# Polarfire SoC register map
Vendor: Microchip; File version: 1.0
CPU: Microchip PolarFire SoC 1.0, little endian
Registers are 32-bit, read-write, reset 0x0 unless marked. A register's access mark holds for its fields unless they carry their own. Offsets are from the block's base; [hi:lo] are bit positions; {n}, {i} and the like mark numbered series; 'fields as' and 'values as' point back to an identical list.

## SYSREG — SYSREG Controller
Base 0x20002000
0x00 TEMP0 reset 0xAC7E1 — Register for software use
  [31:0] DATA — Scratch register for CPUS
0x04 TEMP1 — Register for software use
  [31:0] DATA — Scratch register for CPUS
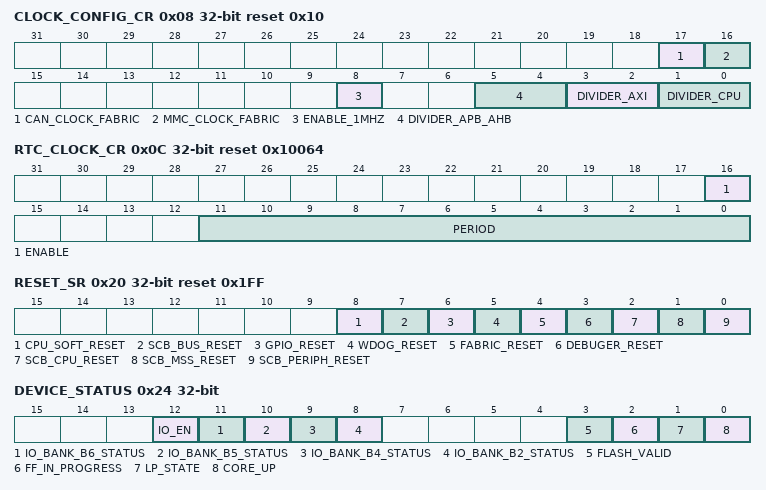
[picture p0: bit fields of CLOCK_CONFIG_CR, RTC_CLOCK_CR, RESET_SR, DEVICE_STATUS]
0x08 CLOCK_CONFIG_CR reset 0x10 — Master clock configuration
  [17] CAN_CLOCK_FABRIC
  [16] MMC_CLOCK_FABRIC
  [8] ENABLE_1MHZ — When '1' requests pfsoc_control to enable the 1mHz (2MHz) on-chip oscillator
  [5:4] DIVIDER_APB_AHB — Sets the master synchronous clock divider AHB/APB clock divider (Reset=/2 =1) 00=/1 01=/2 10=/4 11=/8 (AHB/APB divider may not be set to /1)
  [3:2] DIVIDER_AXI — Sets the master synchronous clock divider for AXI clock divider (Reset=/1 =0)
  [1:0] DIVIDER_CPU — Sets the master synchronous clock divider for CPU (Reset=/1 =0). Note at reset MSS corner clock is 80MHz, therefore divider is set to divide by 1
0x0C RTC_CLOCK_CR reset 0x10064 — RTC clock divider
  [16] ENABLE — RTC Clock enable. When chaning the divider the enable should be trurned off first, the divider changed and the enable turned back on.
  [11:0] PERIOD — Sets the division ratio to create the internal RTC clock from the reference clock. The defaults sets the reference clock to 1MHz assuming the reference clock is 100Mhz. If the reference clock is 125MHz then 125 will create a 1MHz clock Max divider value is 4095 and value must be an integer. RTC clock must be less 2X the AXI clock rate.
0x10 FABRIC_RESET_CR — Fabric Reset mask
  [0] ENABLE — This bitfield has no affect if changed
0x14 BOOT_FAIL_CR
  [0] BOOT — Written by firmware to indicate that the boot process failed, drives the fab_boot_fail signal to the fabric. Is cleared by the fabric asserting fab_boot_fail_clear
0x18 MSS_RESET_CR — Allows the CPU to fully reset the MSS
  [15:0] RESET_VALUE — When written to 16'hDEAD will cause a full MSS reset. The Reset wil clear this register. The register may be writtent to any value but only a value off 16'hDEAD will cause the reset to happen
0x1C CONFIG_LOCK_CR — Configuration lock
  [0] LOCK — When written to '1' will cause all RWC registers to lock until a master reset occurs.
0x20 RESET_SR reset 0x1FF — Indicates which reset caused the last reset. After a reset occurs register should be read and then zero written to allow the next reset event to be correctly captured.
  [8] CPU_SOFT_RESET — Indicates that the CPU reset ths MSS using the soft reset register
  [7] SCB_BUS_RESET — Indicates that SCB bus reset occurred (which causes warm reset of MSS)
  [6] GPIO_RESET — Indicates that fabric asserted the GPIO reset inputs
  [5] WDOG_RESET — Reset was caused by the watchdog
  [4] FABRIC_RESET — Reset was caused by the fabric
  [3] DEBUGER_RESET — Reset was caused by the Risc-V Debugger
  [2] SCB_CPU_RESET — Reset was caused by the SCB CPU reset register
  [1] SCB_MSS_RESET — Reset was caused by the SCB MSS reset register
  [0] SCB_PERIPH_RESET — Reset was caused by the SCB periphery reset signal
0x24 DEVICE_STATUS ro — Indicates the device status, in particular the state of the FPGA fabric and the MSS IO banks
  [12] IO_EN — Indicates the status of the io_en input from G5 Control.
  [11] IO_BANK_B6_STATUS — Power status of IO bank 6
  [10] IO_BANK_B5_STATUS — Power status of IO bank 5
  [9] IO_BANK_B4_STATUS — Power status of IO bank 4
  [8] IO_BANK_B2_STATUS — Power status of IO bank 2
  [3] FLASH_VALID — Indicates the status of the flash_valid input from G5 Control.
  [2] FF_IN_PROGRESS — Indicates the status of the ff_in_progress input from G5 Control.
  [1] LP_STATE — Indicates the status of the lp_state input from G5 Control.
  [0] CORE_UP — Indicates the status of the core_up input from G5 Control.
0x28 MSS_BUILD ro — MSS Build Info
  [31:0] REVISION — Set to the SVN revision of the pfsoc_mss_main.sv file
{0x3C+4i} FAB_INTEN_U54_{i} (i=1..4) — U54-{i} Fabric interrupt enable
  [31:0] ENABLE — Enables the F2H_interrupts[31:0] to interrupt U54_1 directly
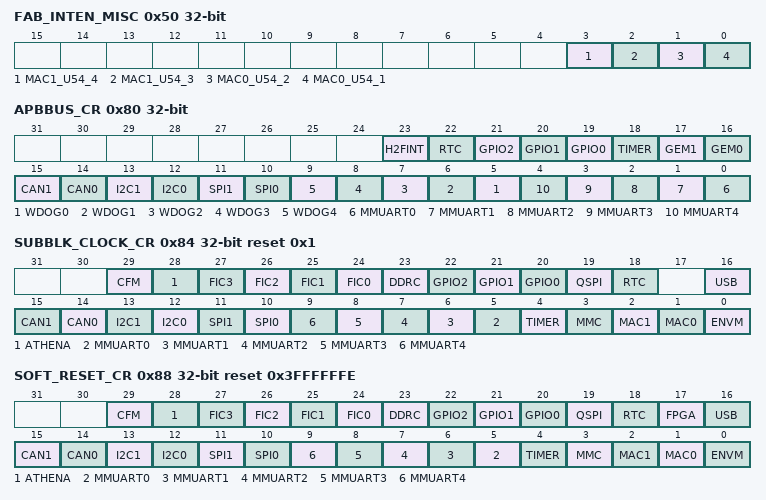
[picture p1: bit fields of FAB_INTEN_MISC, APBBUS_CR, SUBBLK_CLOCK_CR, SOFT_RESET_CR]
0x50 FAB_INTEN_MISC — Allows the Ethernat interrupts to be directly routed to the U54 CPUS.
  [3] MAC1_U54_4 — Enables the Ethernet MAC1 to interrupt U54_1 directly
  [2] MAC1_U54_3 — Enables the Ethernet MAC1 to interrupt U54_1 directly
  [1] MAC0_U54_2 — Enables the Ethernet MAC0 to interrupt U54_1 directly
  [0] MAC0_U54_1 — Enables the Ethernet MAC0 to interrupt U54_1 directly
0x54 GPIO_INTERRUPT_FAB_CR — Switches GPIO interrupt from PAD to Fabric GPIO
  [31:0] SELECT — Setting these bits will disable the Pad interrupt, and enable the fabric GPIO interrupt for bits 31:0. When the bit is set the Pad interrupt will be ORED into the GPIO0 & GPIO1 non-direct interrupts. When the bit is not set the Fabric interrupt is ORED into the GPIO2 non-direct interrupt. To prevent ORING then the interrupt should not be enabled in the GPIO block
0x80 APBBUS_CR — AMP Mode peripheral mapping register. When the register bit is '0' the peripheral is mapped into the 0x2000000 address range using AXI bus 5 from the Coreplex. When the register bit is '1' the peripheral is mapped into the 0x28000000 address range using AXI bus 6 from the Coreplex.
  [23] H2FINT, [22] RTC, [21] GPIO2, [20] GPIO1, [19] GPIO0, [18] TIMER, [17] GEM1, [16] GEM0, [15] CAN1, [14] CAN0, [13] I2C1, [12] I2C0, [11] SPI1, [10] SPI0, [n+5] WDOG{n} (n=0..4), [n] MMUART{n} (n=0..4)
0x84 SUBBLK_CLOCK_CR reset 0x1 — Enables the clock to the MSS peripheral. By turning clocks off dynamic power can be saved. When the clock is off the peripheral should not be accessed, the acess may be ignored, return unspecified data or result in bus response error.
  [29] CFM, [28] ATHENA, [n+24] FIC{n} (n=0..3), [23] DDRC, [22] GPIO2, [21] GPIO1, [20] GPIO0, [19] QSPI, [18] RTC, [16] USB, [15] CAN1, [14] CAN0, [13] I2C1, [12] I2C0, [11] SPI1, [10] SPI0, [n+5] MMUART{n} (n=0..4), [4] TIMER, [3] MMC, [2] MAC1, [1] MAC0, [0] ENVM
0x88 SOFT_RESET_CR reset 0x3FFFFFFE — Holds the MSS peripherals in reset. Whenin reset the peripheral should not be accessed, the acess may be ignored, return unspecified data or result in bus response error.
  [29] CFM, [28] ATHENA, [n+24] FIC{n} (n=0..3), [23] DDRC, [22] GPIO2, [21] GPIO1, [20] GPIO0, [19] QSPI, [18] RTC, [17] FPGA, [16] USB, [15] CAN1, [14] CAN0, [13] I2C1, [12] I2C0, [11] SPI1, [10] SPI0, [n+5] MMUART{n} (n=0..4), [4] TIMER, [3] MMC, [2] MAC1, [1] MAC0, [0] ENVM
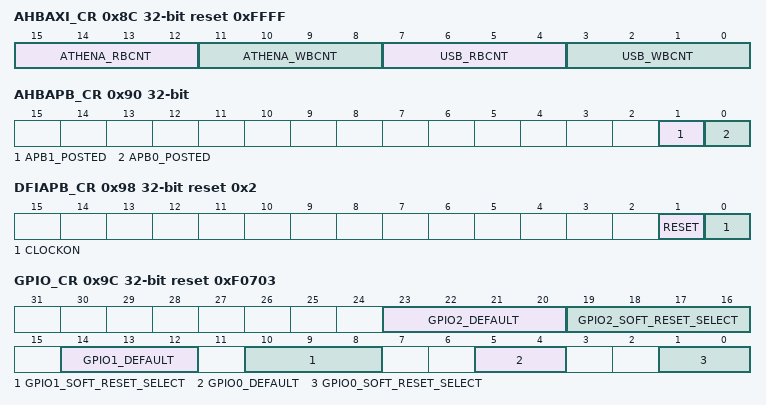
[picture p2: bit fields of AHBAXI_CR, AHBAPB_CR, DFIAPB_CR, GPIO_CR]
0x8C AHBAXI_CR reset 0xFFFF — Configures how many outstanding transfers the AXI-AHB bridges in front off the USB and Crypto blocks should allow. (See Synopsys AXI-AHB bridge documentation)
  [15:12] ATHENA_RBCNT — Number of outstanding read transactions to Athena block
  [11:8] ATHENA_WBCNT — Number of outstanding write transactions to Athena block
  [7:4] USB_RBCNT — Number of outstanding read transactions to USB block
  [3:0] USB_WBCNT — Number of outstanding write transactions to USB block
0x90 AHBAPB_CR — Configures the two AHB-APB bridges on S5 and S6
  [1] APB1_POSTED — Enables posted mode on the AHB-APB bridge, when set the AHB write cycle will complete before the APB write cycle completes.
  [0] APB0_POSTED — Enables posted mode on the AHB-APB bridge, when set the AHB write cycle will complete before the APB write cycle completes.
0x98 DFIAPB_CR reset 0x2 — MSS Corner APB interface controls
  [1] RESET — Asserts the APB reset to the MSS corner, is asserted at MSS reset.
  [0] CLOCKON — Turns on the APB clock to the MSS Corner, is off at reset. Once corner blocks is configured the firmware may turn off the clock, but periodically should turn back on to allow refresh of TMR registers inside the corner block.
0x9C GPIO_CR reset 0xF0703 — GPIO Blocks reset control
  [23:20] GPIO2_DEFAULT — Sets the reset value off the GPIO0 per byte Bit 0 controls GPIO0 [7:0] ,bit 1 GPIO[15:8] and bit 1 GPIO[23:16], and bit 3 GPIO[31:24]
  [19:16] GPIO2_SOFT_RESET_SELECT — This signal selects whether the associated byte is reset by soft reset or the the MSS_GPIO_RESET_N signal from the FPGA fabric. The allowed values are: • 0: Selects MSS_GPIO_RESET_N signal from the FPGA fabric. • 1: Selects the GPIO to be reset by the GPIO block soft reset signal . Bit 0 controls GPIO0 [7:0] ,bit 1 GPIO[15:8] and bit 1 GPIO[23:16], and bit 3 GPIO[31:24] The master MSS reset will also reset the GPIO register if not configured to use fabric reset.
  [14:12] GPIO1_DEFAULT — Sets the reset value off the GPIO0 per byte Bit 0 controls GPIO0 [7:0] ,bit 1 GPIO[15:8] and bit 2 GPIO[23:16]
  [10:8] GPIO1_SOFT_RESET_SELECT — This signal selects whether the associated byte is reset by soft reset or the the MSS_GPIO_RESET_N signal from the FPGA fabric. The allowed values are: • 0: Selects MSS_GPIO_RESET_N signal from the FPGA fabric. • 1: Selects the GPIO to be reset by the GPIO block soft reset signal . Bit 0 controls GPIO0 [7:0] ,bit 1 GPIO[15:8] and bit 2 GPIO[23:16] The master MSS reset will also reset the GPIO register if not configured to use fabric reset.
  [5:4] GPIO0_DEFAULT — Sets the reset value off the GPIO0 per byte Bit 0 controls GPIO0 [7:0] , and bit 1 GPIO[15:8]
  [1:0] GPIO0_SOFT_RESET_SELECT — This signal selects whether the associated byte is reset by soft reset or the the MSS_GPIO_RESET_N signal from the FPGA fabric. The allowed values are: • 0: Selects MSS_GPIO_RESET_N signal from the FPGA fabric. • 1: Selects the GPIO to be reset by the GPIO block soft reset signal . Bit 0 controls GPIO0 [7:0] , and bit 1 GPIO[15:8] The master MSS reset will also reset the GPIO register if not configured to use fabric reset.
0xA4 MAC0_CR ro — MAC0 configuration register
  [3:0] SPEED_MODE — Current speed mode on the MAC
0xA8 MAC1_CR ro — MAC1 configuration register
  [3:0] SPEED_MODE — Current speed mode on the MAC
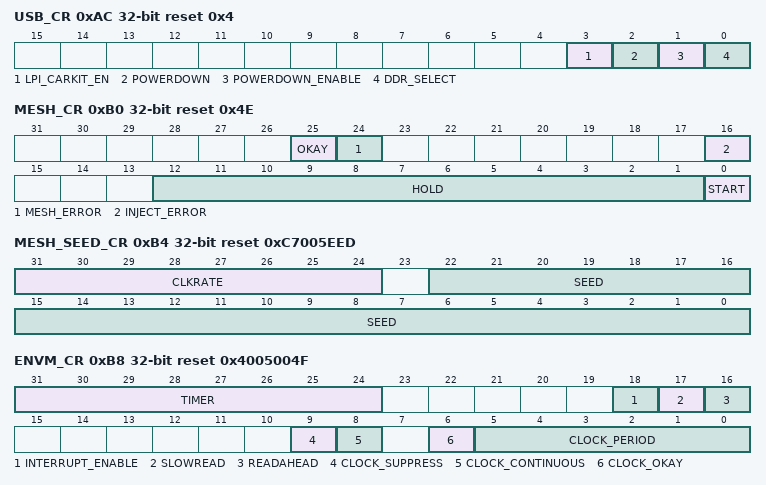
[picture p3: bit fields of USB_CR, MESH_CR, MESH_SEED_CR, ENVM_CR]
0xAC USB_CR reset 0x4 — USB Configuration register
  [3] LPI_CARKIT_EN ro — Set when entry is made into CarKit mode and cleared on exit from CarKit mode.
  [2] POWERDOWN ro — Indicates that the USB CLK may be stopped to save power. Derived from combination of signals from CLK & XCLK flip-flops, AVALID, VBUSVALID and LINESTATE. When asserted the USB clock into the core is stopped.
  [1] POWERDOWN_ENABLE — When '1' will stops the clock to the USB core when the core asserts its POWERDOWN output. For G4 compatability this bit defaults to 0.
  [0] DDR_SELECT ro — Configures USB for Single-Data Rate(SDR) mode or Double-Data Rate(DDR) mode. 0 - SDR Mode is selected 1 - DDR Mode is selected (Not supported in G5 or G5)
0xB0 MESH_CR reset 0x4E — Crypto Mesh control and status register
  [25] OKAY ro — Indicates that the Mesh is functioning correctly. Will be set approximately 520 clock cycles after mesh started and stay set as long as the mesh is not detecting any errors.
  [24] MESH_ERROR — Indicates that Mesh detected an error. Cleared by writing a '1'
  [16] INJECT_ERROR — When set will inject an error in the mesh
  [12:1] HOLD — Sets the amount of time that the mesh is held active for, actual hold time includes up to 256 us of random variation. Minimum Time = 1 + 256 * value us Maximum Time = 1 + 256 * (1+value) us Value must be greater than 0
  [0] START — Writing a 1 will start the Mesh System
0xB4 MESH_SEED_CR reset 0xC7005EED — Crypto mesh seed and update rate
  [31:24] CLKRATE — Sets the rate that the mesh value is changed. Rate = AHBCLK/(clkrate+1). Rate must be less than 1MHz, setting slower will reduce power consumption.
  [22:0] SEED — Sets the mesh seed value, any value may be used, zero should be avoided
0xB8 ENVM_CR reset 0x4005004F — ENVM AHB Controller setup
  [31:24] TIMER — Sets the duration of the timer used to detect a non response of slow response from the PNVM on C and R bus accesses. Timer Duration = Value * (1000/AHBFREQMHZ) 0x00: Timer dissabled. If the timer expires the AHB cycle is terminates using the HRESP protocol
  [18] INTERRUPT_ENABLE — Enable the ENVM interrupt
  [17] SLOWREAD — When '1' the controller will initate separate ENVM reads for all reads. No buffering or speculative operations will be carried out. When performing word reads incrementing through PNVM each location will be read twice (intended for test use)
  [16] READAHEAD — Enables "readahead" on the ENVM controller. The controller will automatically read the next PNVM location as soon as possible ahead of the AHB request. This will improve read performance when incrementing though memory as the NVM reads and AHB cycles are pipelined. When set non incrementing accesses will take longer as the controller may be in the process of reading the next address and the PNVM cycle needs to complete prior to starting the required read
  [9] CLOCK_SUPPRESS — When set suppresses clock edge between C-Bus access cycles so that they appear as consecutive access cycles.
  [8] CLOCK_CONTINUOUS — When '1' the PNVM clock will be always generated, and not stopped between access cycles. Setting this will increase access latency but mean that the PNVM clock operates at a stable rate.
  [6] CLOCK_OKAY ro — Indicates the eNVM is running at the configured divider rate.
  [5:0] CLOCK_PERIOD — Sets the number of AHB cycles used to generate the PNVM clock, Clock period = (Value+1) * (1000/AHBFREQMHZ) Value must be 1 to 63 (0 defaults to 15) e.g. 11 will generate a 40ns period 25MHz clock if the AHB clock is 250MHz 15 will generate a 40ns period 25MHz clock if the AHB clock is 400MHz
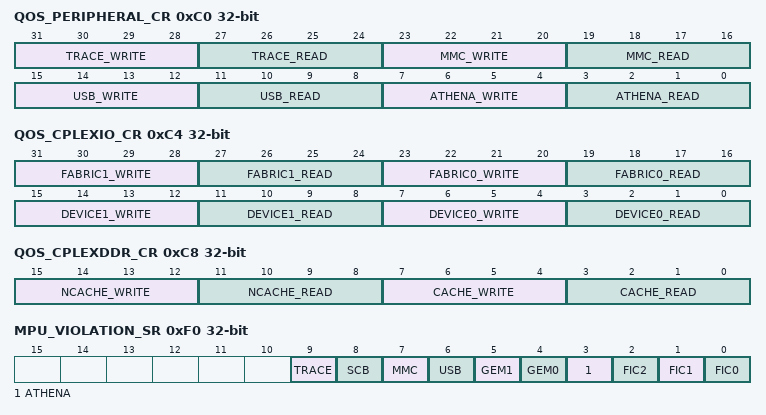
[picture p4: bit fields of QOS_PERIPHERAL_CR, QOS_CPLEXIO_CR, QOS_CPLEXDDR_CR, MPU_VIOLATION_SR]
0xC0 QOS_PERIPHERAL_CR — QOS Athena, USB & MMC Configuration
  [31:28] TRACE_WRITE — Sets the QOS value from the specified device into the switch
  [27:24] TRACE_READ — Sets the QOS value from the specified device into the switch
  [23:20] MMC_WRITE — Sets the QOS value from the specified device into the switch
  [19:16] MMC_READ — Sets the QOS value from the specified device into the switch
  [15:12] USB_WRITE — Sets the QOS value from the specified device into the switch
  [11:8] USB_READ — Sets the QOS value from the specified device into the switch
  [7:4] ATHENA_WRITE — Sets the QOS value from the specified device into the switch
  [3:0] ATHENA_READ — Sets the QOS value from the specified device into the switch
0xC4 QOS_CPLEXIO_CR — QOS Configuration Coreplex
  [31:28] FABRIC1_WRITE — Sets the QOS value from the specified device into the switch
  [27:24] FABRIC1_READ — Sets the QOS value from the specified device into the switch
  [23:20] FABRIC0_WRITE — Sets the QOS value from the specified device into the switch
  [19:16] FABRIC0_READ — Sets the QOS value from the specified device into the switch
  [15:12] DEVICE1_WRITE — Sets the QOS value from the specified device into the switch
  [11:8] DEVICE1_READ — Sets the QOS value from the specified device into the switch
  [7:4] DEVICE0_WRITE — Sets the QOS value from the specified device into the switch
  [3:0] DEVICE0_READ — Sets the QOS value from the specified device into the switch
0xC8 QOS_CPLEXDDR_CR — QOS configuration DDRC
  [15:12] NCACHE_WRITE — Sets the QOS value from the specified device into the switch
  [11:8] NCACHE_READ — Sets the QOS value from the specified device into the switch
  [7:4] CACHE_WRITE — Sets the QOS value from the specified device into the switch
  [3:0] CACHE_READ — Sets the QOS value from the specified device into the switch
0xF0 MPU_VIOLATION_SR — Indicates that a master caused a MPU violation. Interrupts via maintenance interrupt.
  [9] TRACE — Bit is set on violation. Cleared by writing '1'
  [8] SCB — Bit is set on violation. Cleared by writing '1'
  [7] MMC — Bit is set on violation. Cleared by writing '1'
  [6] USB — Bit is set on violation. Cleared by writing '1'
  [5] GEM1 — Bit is set on violation. Cleared by writing '1'
  [4] GEM0 — Bit is set on violation. Cleared by writing '1'
  [3] ATHENA — Bit is set on violation. Cleared by writing '1'
  [2] FIC2 — Bit is set on violation. Cleared by writing '1'
  [1] FIC1 — Bit is set on violation. Cleared by writing '1'
  [0] FIC0 — Bit is set on violation. Cleared by writing '1'
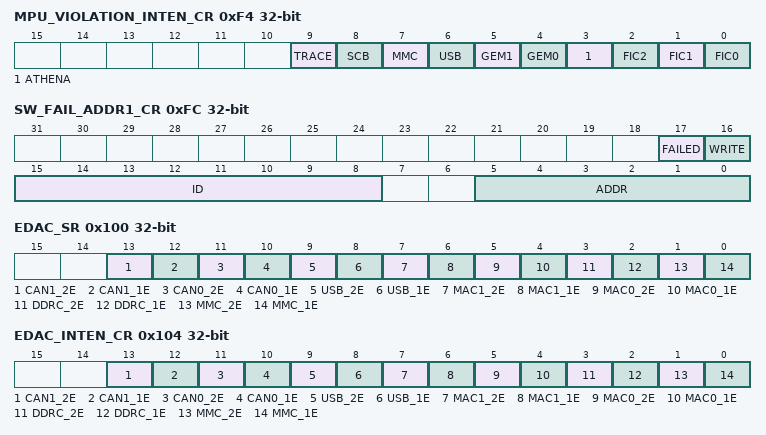
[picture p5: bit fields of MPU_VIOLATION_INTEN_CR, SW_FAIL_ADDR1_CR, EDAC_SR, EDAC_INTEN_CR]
0xF4 MPU_VIOLATION_INTEN_CR — Enables interrupts on MPU violations
  [9] TRACE — Enables the interrupt
  [8] SCB — Enables the interrupt
  [7] MMC — Enables the interrupt
  [6] USB — Enables the interrupt
  [5] GEM1 — Enables the interrupt
  [4] GEM0 — Enables the interrupt
  [3] ATHENA — Enables the interrupt
  [2] FIC2 — Enables the interrupt
  [1] FIC1 — Enables the interrupt
  [0] FIC0 — Enables the interrupt
0xF8 SW_FAIL_ADDR0_CR ro — AXI switch decode fail
  [31:0] ADDR — The address (bits 31:0) that failed. Redaing this address as 64-bits will return the 38-bit address in assingle read combined with additional information in the next register
0xFC SW_FAIL_ADDR1_CR — AXI switch decode fail
  [17] FAILED
  [16] WRITE ro — AXI write=1 or read=0
  [15:8] ID ro — AXI ID off failure
  [5:0] ADDR ro — Upper 6 bits off address [37:32]
0x100 EDAC_SR — Set when an ECC event happens
  [13] CAN1_2E, [12] CAN1_1E, [11] CAN0_2E, [10] CAN0_1E, [9] USB_2E, [8] USB_1E, [7] MAC1_2E, [6] MAC1_1E, [5] MAC0_2E, [4] MAC0_1E, [3] DDRC_2E, [2] DDRC_1E, [1] MMC_2E, [0] MMC_1E
0x104 EDAC_INTEN_CR — Enables ECC interrupt on event
  fields as EDAC_SR
0x108 EDAC_CNT_MMC — Count off single bit errors
  [9:0] COUNT
0x10C EDAC_CNT_DDRC — Count off single bit errors
  [9:0] COUNT
0x110 EDAC_CNT_MAC0 — Count off single bit errors
  [9:0] COUNT
0x114 EDAC_CNT_MAC1 — Count off single bit errors
  [9:0] COUNT
0x118 EDAC_CNT_USB — Count off single bit errors
  [9:0] COUNT
0x11C EDAC_CNT_CAN0 — Count off single bit errors
  [9:0] COUNT
0x120 EDAC_CNT_CAN1 — Count off single bit errors
  [9:0] COUNT
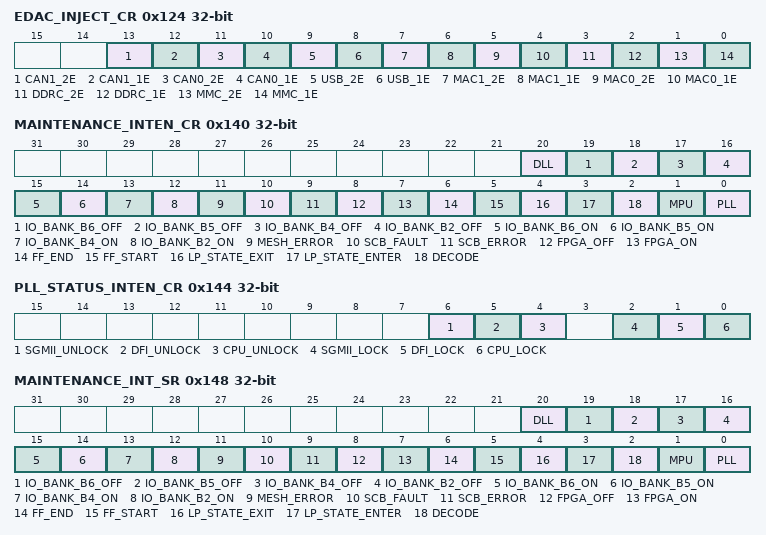
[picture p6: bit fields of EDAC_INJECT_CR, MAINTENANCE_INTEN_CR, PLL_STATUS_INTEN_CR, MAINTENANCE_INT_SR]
0x124 EDAC_INJECT_CR — Will Corrupt write data to rams, 1E corrupts bit 0, 2E bits 1 and 2. Injects Errors into all RAMS in the block as long as the bits are set. Setting 1E and 2E will inject a 3-bit error
  fields as EDAC_SR
0x140 MAINTENANCE_INTEN_CR — Maintenance Interrupt Enable.
  [20] DLL — Enables interrupt on a DLL event, DLL_STATUS_INTEN_CR should also be set
  [19] IO_BANK_B6_OFF — Enables interrupt on bank6 powered off
  [18] IO_BANK_B5_OFF — Enables interrupt on bank5 powered off
  [17] IO_BANK_B4_OFF — Enables interrupt on bank4 powered off
  [16] IO_BANK_B2_OFF — Enables interrupt on bank2 powered off
  [15] IO_BANK_B6_ON — Enables interrupt on bank6 powered on
  [14] IO_BANK_B5_ON — Enables interrupt on bank5 powered on
  [13] IO_BANK_B4_ON — Enables interrupt on bank4 powered on
  [12] IO_BANK_B2_ON — Enables interrupt on bank2 powered on
  [11] MESH_ERROR — Enables interrupt on Mesh violation detection
  [10] SCB_FAULT — Enables interrupt on SCB failure
  [9] SCB_ERROR — Enables interrupt on SCB error
  [8] FPGA_OFF — Enables interrupt when FPGA turned off
  [7] FPGA_ON — Enables interrupt when FPGA turned on
  [6] FF_END — Enables interrupt as flash_freeze goes low
  [5] FF_START — Enables interrupt as flash_freeze goes high
  [4] LP_STATE_EXIT — Enables interrupt as lp_state goes low
  [3] LP_STATE_ENTER — Enables interrupt as lp_state goes high
  [2] DECODE — Enables interrupt on a AXI switch decode error
  [1] MPU — Enables interrupt on a MPU access violation
  [0] PLL — Enables interrupt on a PLL event, PLL_STATUS_INTEN_CR should also be set
0x144 PLL_STATUS_INTEN_CR — PLL Status interrupt enables
  [6] SGMII_UNLOCK — Enables interrupt on SGMII PLL unlocking
  [5] DFI_UNLOCK — Enables interrupt on DFT PLL unlocking
  [4] CPU_UNLOCK — Enables interrupt on CPU PLL unlocking
  [2] SGMII_LOCK — Enables interrupt on SGMII PLL locking
  [1] DFI_LOCK — Enables interrupt on DFT PLL locking
  [0] CPU_LOCK — Enables interrupt on CPU PLL locking
0x148 MAINTENANCE_INT_SR — Maintenace interrupt, indicates fault and status events.
  [20] DLL ro — Indicates that IO bank 6 has turned off, cleared by writing a '1'
  [19] IO_BANK_B6_OFF — Indicates that one off the DLLs whent into the lock or unlock state. Cleared via DLL status register
  [18] IO_BANK_B5_OFF — Indicates that IO bank 5 has turned off, cleared by writing a '1'
  [17] IO_BANK_B4_OFF — Indicates that IO bank 4 has turned off, cleared by writing a '1'
  [16] IO_BANK_B2_OFF — Indicates that IO bank 2 has turned off, cleared by writing a '1'
  [15] IO_BANK_B6_ON — Indicates that IO bank 6 has turned on, cleared by writing a '1'
  [14] IO_BANK_B5_ON — Indicates that IO bank 5 has turned on, cleared by writing a '1'
  [13] IO_BANK_B4_ON — Indicates that IO bank 4 has turned on, cleared by writing a '1'
  [12] IO_BANK_B2_ON — Indicates that IO bank 2 has turned on, cleared by writing a '1'
  [11] MESH_ERROR ro — Indicates that the mesh over the Crypto triggered, cleared via Mesh system error
  [10] SCB_FAULT ro — Indicates that the SCB bus fault occurred, cleared via SCB controller
  [9] SCB_ERROR ro — Indicates that the SCB slave reported an error, cleared via SCB controller
  [8] FPGA_OFF — Indicates that the FPGA array has been turned off, cleared by writing a '1'
  [7] FPGA_ON — Indicates that the FPGA array has been turned on, cleared by writing a '1'
  [6] FF_END — Indicates the device has exited the flash freezer state, cleared by writing '1'
  [5] FF_START — Indicates the device has entered the flash freezer state, cleared by writing '1'
  [4] LP_STATE_EXIT — Indicates the device has exited the lower power state, cleared by writing '1'
  [3] LP_STATE_ENTER — Indicates the device has entered the lower power state, cleared by writing '1'
  [2] DECODE ro — Indicates that the AXI switch detected an illegal address. Cleared when SREG.SW_FAIL.ADDR1_CR_FAILED is cleared.
  [1] MPU ro — Indicates that one off the MPUS signaled a MPU violation. Cleared via MPU Violation Register
  [0] PLL ro — Indicates that one off the PLLs whent into the lock or unlock state. Cleared via PLL status register
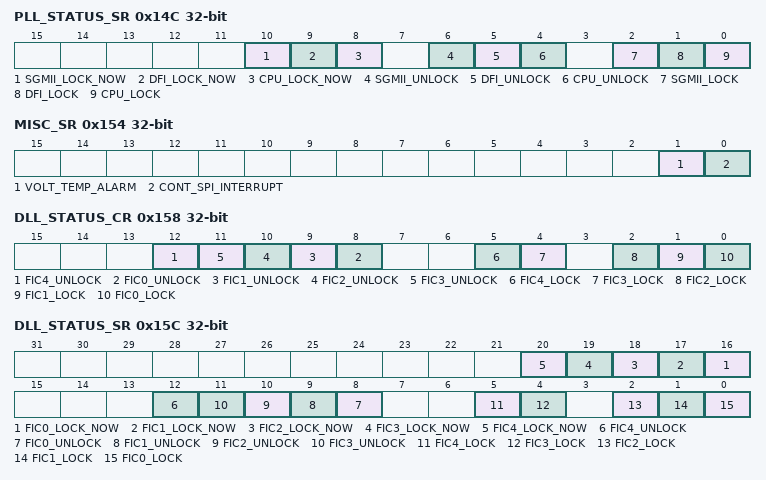
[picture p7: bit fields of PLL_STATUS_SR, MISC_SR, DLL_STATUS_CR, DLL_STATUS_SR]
0x14C PLL_STATUS_SR — PLL interrupt register
  [10] SGMII_LOCK_NOW ro — Current state off SGMII PLL locked signal
  [9] DFI_LOCK_NOW ro — Current state off DFI PLL locked signal
  [8] CPU_LOCK_NOW ro — Current state off CPU PLL locked signal
  [6] SGMII_UNLOCK — Indicates that the SGMII PLL has unlocked, cleared by writing a '1'
  [5] DFI_UNLOCK — Indicates that the DFI PLL has unlocked, cleared by writing a '1'
  [4] CPU_UNLOCK — Indicates that the CPU PLL has unlocked, cleared by writing a '1'
  [2] SGMII_LOCK — Indicates that the SGMII PLL has locked, cleared by writing a '1'
  [1] DFI_LOCK — Indicates that the DFI PLL has locked, cleared by writing a '1'
  [0] CPU_LOCK — Indicates that the CPU PLL has locked, cleared by writing a '1'
0x150 CFM_TIMER_CR — Enable to CFM Timer
  [4:0] ENABLE — When set and the CFM channel is in timer mode and CFM channel is set to 2 (Group C) this register allows the timet to count. Allows software to start and stop the timers.
0x154 MISC_SR ro — Miscellanous Register
  [1] VOLT_TEMP_ALARM — Indicates that the user voltage or temperature detectors are signalling an alarm condition.
  [0] CONT_SPI_INTERRUPT — Indicates that Interrupt from the PFC MSS SCB SPI controller is active
0x158 DLL_STATUS_CR — DLL Interrupt enables
  [12] FIC4_UNLOCK — Enables the DLL4 (crypto) unlock interrupt
  [n+8] FIC{n}_UNLOCK (n=0..3) — Enables the DLL{n} unlock interrupt
  [5] FIC4_LOCK — Enables the DLL4 (Crypto) lock interrupt
  [4] FIC3_LOCK — Enables the DLL3 lock interrupt
  [2] FIC2_LOCK — Enables the DLL2 lock interrupt
  [1] FIC1_LOCK — Enables the DLL1 lock interrupt
  [0] FIC0_LOCK — Enables the DLL0 lock interrupt
0x15C DLL_STATUS_SR — DLL interrupt register
  [n+16] FIC{n}_LOCK_NOW ro (n=0..4) — Current state off FIC{n} DLL locked signal
  [12] FIC4_UNLOCK — Indicates that the FIC4 (Crypto) DLL has unlocked, cleared by writing a '1'
  [n+8] FIC{n}_UNLOCK (n=0..3) — Indicates that the FIC{n} DLL has unlocked, cleared by writing a '1'
  [5] FIC4_LOCK — Indicates that the FIC4 (Crypto) DLL has locked, cleared by writing a '1'
  [4] FIC3_LOCK — Indicates that the FIC3 DLL has locked, cleared by writing a '1'
  [2] FIC2_LOCK — Indicates that the FIC2 DLL has locked, cleared by writing a '1'
  [1] FIC1_LOCK — Indicates that the FIC1 DLL has locked, cleared by writing a '1'
  [0] FIC0_LOCK — Indicates that the FIC0 DLL has locked, cleared by writing a '1'
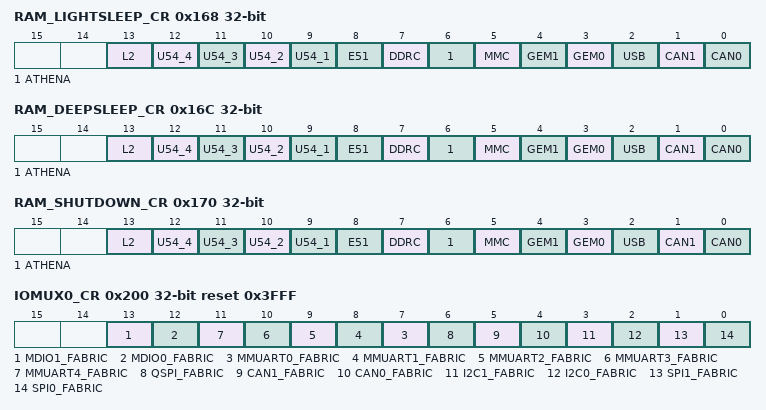
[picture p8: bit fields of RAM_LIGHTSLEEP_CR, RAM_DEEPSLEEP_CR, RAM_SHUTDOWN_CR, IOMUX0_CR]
0x168 RAM_LIGHTSLEEP_CR — Puts all the RAMS in that block into low leakage mode. RAM contents and Q value preserved.
  [13] L2, [n+8] U54_{n} (n=1..4), [8] E51, [7] DDRC, [6] ATHENA, [5] MMC, [4] GEM1, [3] GEM0, [2] USB, [1] CAN1, [0] CAN0
0x16C RAM_DEEPSLEEP_CR — Puts all the RAMS in that block into deep sleep mode. RAM contents preserved. Powers down the periphery circuits.
  fields as RAM_LIGHTSLEEP_CR
0x170 RAM_SHUTDOWN_CR — Puts all the RAMS in that block into shut down mode. RAM contents not preserved. Powers down the RAM and periphery circuits.
  fields as RAM_LIGHTSLEEP_CR
0x174 L2_SHUTDOWN_CR — Allows each bank of the L2 Cache to be powered down, orded with global shutdown
  [3:0] L2_RAMS
0x200 IOMUX0_CR reset 0x3FFF — Selects whether the peripheral is connected to the Fabric or IOMUX structure.
  [13] MDIO1_FABRIC, [12] MDIO0_FABRIC, [n+7] MMUART{n}_FABRIC (n=0..4), [6] QSPI_FABRIC, [5] CAN1_FABRIC, [4] CAN0_FABRIC, [3] I2C1_FABRIC, [2] I2C0_FABRIC, [1] SPI1_FABRIC, [0] SPI0_FABRIC
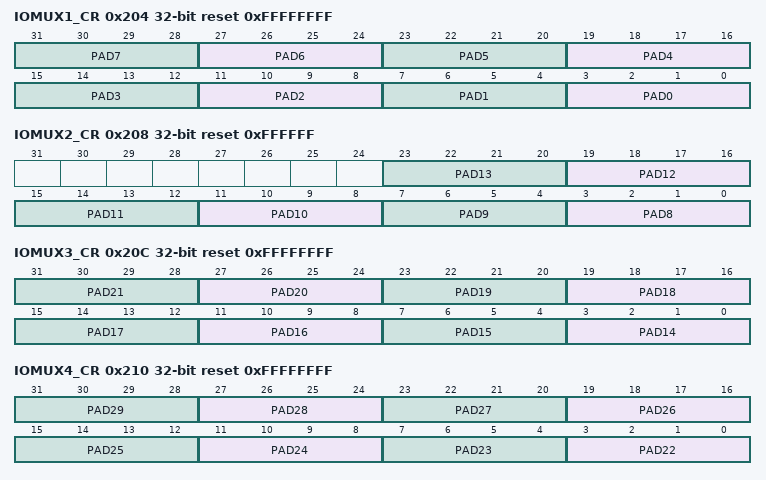
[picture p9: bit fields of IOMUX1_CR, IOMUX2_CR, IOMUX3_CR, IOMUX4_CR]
0x204 IOMUX1_CR reset 0xFFFFFFFF — Configures the IO Mux structure for each IO pad. 0 implies SD/SDIO, 1 implies EMMC, 2 implies QSPI, 3 implies SPI,4 implies USB,5 implies MMUART,6 implies I2C,7 implies CAN,8 implies MDIO,9 implies Miscellaneous,0xA implies Reserved (Equivalent to Tristate),0xB implies GPIO ,0xC implies Fabric-test,0xD implies Logic 0,0xE implies Logic 1, 0xF implies Tristate.
  [4n+3:4n] PAD{n} (n=0..7)
0x208 IOMUX2_CR reset 0xFFFFFF — Configures the IO Mux structure for each IO pad. 0 implies SD/SDIO, 1 implies EMMC, 2 implies QSPI, 3 implies SPI,4 implies USB,5 implies MMUART,6 implies I2C,7 implies CAN,8 implies MDIO,9 implies Miscellaneous,0xA implies Reserved (Equivalent to Tristate),0xB implies GPIO ,0xC implies Fabric-test,0xD implies Logic 0,0xE implies Logic 1, 0xF implies Tristate.
  [4n-29:4n-32] PAD{n} (n=8..13)
0x20C IOMUX3_CR reset 0xFFFFFFFF — Configures the IO Mux structure for each IO pad. 0 implies SD/SDIO, 1 implies EMMC, 2 implies QSPI, 3 implies SPI,4 implies USB,5 implies MMUART,6 implies I2C,7 implies CAN,8 implies MDIO,9 implies Miscellaneous,0xA implies Reserved (Equivalent to Tristate),0xB implies GPIO ,0xC implies Fabric-test,0xD implies Logic 0,0xE implies Logic 1, 0xF implies Tristate.
  [4n-53:4n-56] PAD{n} (n=14..21)
0x210 IOMUX4_CR reset 0xFFFFFFFF — Configures the IO Mux structure for each IO pad. 0 implies SD/SDIO, 1 implies EMMC, 2 implies QSPI, 3 implies SPI,4 implies USB,5 implies MMUART,6 implies I2C,7 implies CAN,8 implies MDIO,9 implies Miscellaneous,0xA implies Reserved (Equivalent to Tristate),0xB implies GPIO ,0xC implies Fabric-test,0xD implies Logic 0,0xE implies Logic 1, 0xF implies Tristate.
  [4n-85:4n-88] PAD{n} (n=22..29)
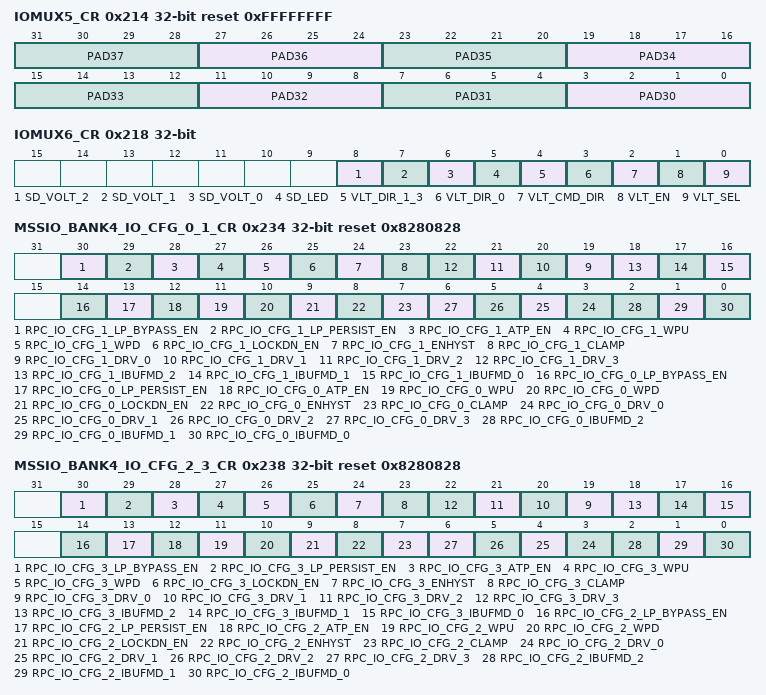
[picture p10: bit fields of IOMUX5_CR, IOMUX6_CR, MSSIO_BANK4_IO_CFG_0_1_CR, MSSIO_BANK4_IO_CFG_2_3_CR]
0x214 IOMUX5_CR reset 0xFFFFFFFF — Configures the IO Mux structure for each IO pad. 0 implies SD/SDIO, 1 implies EMMC, 2 implies QSPI, 3 implies SPI,4 implies USB,5 implies MMUART,6 implies I2C,7 implies CAN,8 implies MDIO,9 implies Miscellaneous,0xA implies Reserved (Equivalent to Tristate),0xB implies GPIO ,0xC implies Fabric-test,0xD implies Logic 0,0xE implies Logic 1, 0xF implies Tristate.
  [4n-117:4n-120] PAD{n} (n=30..37)
0x218 IOMUX6_CR — Sets whether the MMC/SD Voltage select lines are inverted on entry to the IOMUX structure
  [8] SD_VOLT_2, [7] SD_VOLT_1, [6] SD_VOLT_0, [5] SD_LED, [4] VLT_DIR_1_3, [3] VLT_DIR_0, [2] VLT_CMD_DIR, [1] VLT_EN, [0] VLT_SEL
0x234 MSSIO_BANK4_IO_CFG_0_1_CR reset 0x8280828 — IO electrical configuration for MSSIO pad
  [30] RPC_IO_CFG_1_LP_BYPASS_EN, [29] RPC_IO_CFG_1_LP_PERSIST_EN, [28] RPC_IO_CFG_1_ATP_EN, [27] RPC_IO_CFG_1_WPU, [26] RPC_IO_CFG_1_WPD, [25] RPC_IO_CFG_1_LOCKDN_EN ro, [24] RPC_IO_CFG_1_ENHYST, [23] RPC_IO_CFG_1_CLAMP, [n+19] RPC_IO_CFG_1_DRV_{n} (n=0..3), [18] RPC_IO_CFG_1_IBUFMD_2, [17] RPC_IO_CFG_1_IBUFMD_1, [16] RPC_IO_CFG_1_IBUFMD_0, [14] RPC_IO_CFG_0_LP_BYPASS_EN, [13] RPC_IO_CFG_0_LP_PERSIST_EN, [12] RPC_IO_CFG_0_ATP_EN, [11] RPC_IO_CFG_0_WPU, [10] RPC_IO_CFG_0_WPD, [9] RPC_IO_CFG_0_LOCKDN_EN ro, [8] RPC_IO_CFG_0_ENHYST, [7] RPC_IO_CFG_0_CLAMP, [n+3] RPC_IO_CFG_0_DRV_{n} (n=0..3), [2] RPC_IO_CFG_0_IBUFMD_2, [1] RPC_IO_CFG_0_IBUFMD_1, [0] RPC_IO_CFG_0_IBUFMD_0
0x238 MSSIO_BANK4_IO_CFG_2_3_CR reset 0x8280828 — IO electrical configuration for MSSIO pad
  [30] RPC_IO_CFG_3_LP_BYPASS_EN, [29] RPC_IO_CFG_3_LP_PERSIST_EN, [28] RPC_IO_CFG_3_ATP_EN, [27] RPC_IO_CFG_3_WPU, [26] RPC_IO_CFG_3_WPD, [25] RPC_IO_CFG_3_LOCKDN_EN ro, [24] RPC_IO_CFG_3_ENHYST, [23] RPC_IO_CFG_3_CLAMP, [n+19] RPC_IO_CFG_3_DRV_{n} (n=0..3), [18] RPC_IO_CFG_3_IBUFMD_2, [17] RPC_IO_CFG_3_IBUFMD_1, [16] RPC_IO_CFG_3_IBUFMD_0, [14] RPC_IO_CFG_2_LP_BYPASS_EN, [13] RPC_IO_CFG_2_LP_PERSIST_EN, [12] RPC_IO_CFG_2_ATP_EN, [11] RPC_IO_CFG_2_WPU, [10] RPC_IO_CFG_2_WPD, [9] RPC_IO_CFG_2_LOCKDN_EN ro, [8] RPC_IO_CFG_2_ENHYST, [7] RPC_IO_CFG_2_CLAMP, [n+3] RPC_IO_CFG_2_DRV_{n} (n=0..3), [2] RPC_IO_CFG_2_IBUFMD_2, [1] RPC_IO_CFG_2_IBUFMD_1, [0] RPC_IO_CFG_2_IBUFMD_0
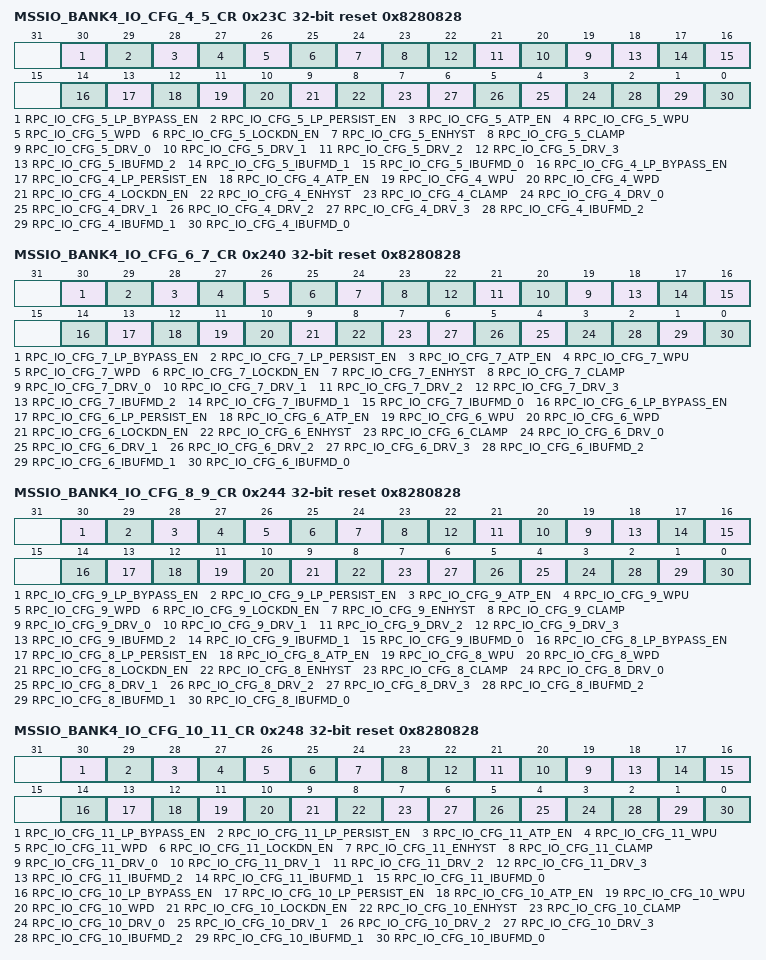
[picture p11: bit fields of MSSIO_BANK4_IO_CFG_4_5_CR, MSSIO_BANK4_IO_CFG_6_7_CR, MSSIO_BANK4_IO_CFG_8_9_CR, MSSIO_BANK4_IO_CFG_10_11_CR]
0x23C MSSIO_BANK4_IO_CFG_4_5_CR reset 0x8280828 — IO electrical configuration for MSSIO pad
  [30] RPC_IO_CFG_5_LP_BYPASS_EN, [29] RPC_IO_CFG_5_LP_PERSIST_EN, [28] RPC_IO_CFG_5_ATP_EN, [27] RPC_IO_CFG_5_WPU, [26] RPC_IO_CFG_5_WPD, [25] RPC_IO_CFG_5_LOCKDN_EN ro, [24] RPC_IO_CFG_5_ENHYST, [23] RPC_IO_CFG_5_CLAMP, [n+19] RPC_IO_CFG_5_DRV_{n} (n=0..3), [18] RPC_IO_CFG_5_IBUFMD_2, [17] RPC_IO_CFG_5_IBUFMD_1, [16] RPC_IO_CFG_5_IBUFMD_0, [14] RPC_IO_CFG_4_LP_BYPASS_EN, [13] RPC_IO_CFG_4_LP_PERSIST_EN, [12] RPC_IO_CFG_4_ATP_EN, [11] RPC_IO_CFG_4_WPU, [10] RPC_IO_CFG_4_WPD, [9] RPC_IO_CFG_4_LOCKDN_EN ro, [8] RPC_IO_CFG_4_ENHYST, [7] RPC_IO_CFG_4_CLAMP, [n+3] RPC_IO_CFG_4_DRV_{n} (n=0..3), [2] RPC_IO_CFG_4_IBUFMD_2, [1] RPC_IO_CFG_4_IBUFMD_1, [0] RPC_IO_CFG_4_IBUFMD_0
0x240 MSSIO_BANK4_IO_CFG_6_7_CR reset 0x8280828 — IO electrical configuration for MSSIO pad
  [30] RPC_IO_CFG_7_LP_BYPASS_EN, [29] RPC_IO_CFG_7_LP_PERSIST_EN, [28] RPC_IO_CFG_7_ATP_EN, [27] RPC_IO_CFG_7_WPU, [26] RPC_IO_CFG_7_WPD, [25] RPC_IO_CFG_7_LOCKDN_EN ro, [24] RPC_IO_CFG_7_ENHYST, [23] RPC_IO_CFG_7_CLAMP, [n+19] RPC_IO_CFG_7_DRV_{n} (n=0..3), [18] RPC_IO_CFG_7_IBUFMD_2, [17] RPC_IO_CFG_7_IBUFMD_1, [16] RPC_IO_CFG_7_IBUFMD_0, [14] RPC_IO_CFG_6_LP_BYPASS_EN, [13] RPC_IO_CFG_6_LP_PERSIST_EN, [12] RPC_IO_CFG_6_ATP_EN, [11] RPC_IO_CFG_6_WPU, [10] RPC_IO_CFG_6_WPD, [9] RPC_IO_CFG_6_LOCKDN_EN ro, [8] RPC_IO_CFG_6_ENHYST, [7] RPC_IO_CFG_6_CLAMP, [n+3] RPC_IO_CFG_6_DRV_{n} (n=0..3), [2] RPC_IO_CFG_6_IBUFMD_2, [1] RPC_IO_CFG_6_IBUFMD_1, [0] RPC_IO_CFG_6_IBUFMD_0
0x244 MSSIO_BANK4_IO_CFG_8_9_CR reset 0x8280828 — IO electrical configuration for MSSIO pad
  [30] RPC_IO_CFG_9_LP_BYPASS_EN, [29] RPC_IO_CFG_9_LP_PERSIST_EN, [28] RPC_IO_CFG_9_ATP_EN, [27] RPC_IO_CFG_9_WPU, [26] RPC_IO_CFG_9_WPD, [25] RPC_IO_CFG_9_LOCKDN_EN ro, [24] RPC_IO_CFG_9_ENHYST, [23] RPC_IO_CFG_9_CLAMP, [n+19] RPC_IO_CFG_9_DRV_{n} (n=0..3), [18] RPC_IO_CFG_9_IBUFMD_2, [17] RPC_IO_CFG_9_IBUFMD_1, [16] RPC_IO_CFG_9_IBUFMD_0, [14] RPC_IO_CFG_8_LP_BYPASS_EN, [13] RPC_IO_CFG_8_LP_PERSIST_EN, [12] RPC_IO_CFG_8_ATP_EN, [11] RPC_IO_CFG_8_WPU, [10] RPC_IO_CFG_8_WPD, [9] RPC_IO_CFG_8_LOCKDN_EN ro, [8] RPC_IO_CFG_8_ENHYST, [7] RPC_IO_CFG_8_CLAMP, [n+3] RPC_IO_CFG_8_DRV_{n} (n=0..3), [2] RPC_IO_CFG_8_IBUFMD_2, [1] RPC_IO_CFG_8_IBUFMD_1, [0] RPC_IO_CFG_8_IBUFMD_0
0x248 MSSIO_BANK4_IO_CFG_10_11_CR reset 0x8280828 — IO electrical configuration for MSSIO pad
  [30] RPC_IO_CFG_11_LP_BYPASS_EN, [29] RPC_IO_CFG_11_LP_PERSIST_EN, [28] RPC_IO_CFG_11_ATP_EN, [27] RPC_IO_CFG_11_WPU, [26] RPC_IO_CFG_11_WPD, [25] RPC_IO_CFG_11_LOCKDN_EN ro, [24] RPC_IO_CFG_11_ENHYST, [23] RPC_IO_CFG_11_CLAMP, [n+19] RPC_IO_CFG_11_DRV_{n} (n=0..3), [18] RPC_IO_CFG_11_IBUFMD_2, [17] RPC_IO_CFG_11_IBUFMD_1, [16] RPC_IO_CFG_11_IBUFMD_0, [14] RPC_IO_CFG_10_LP_BYPASS_EN, [13] RPC_IO_CFG_10_LP_PERSIST_EN, [12] RPC_IO_CFG_10_ATP_EN, [11] RPC_IO_CFG_10_WPU, [10] RPC_IO_CFG_10_WPD, [9] RPC_IO_CFG_10_LOCKDN_EN ro, [8] RPC_IO_CFG_10_ENHYST, [7] RPC_IO_CFG_10_CLAMP, [n+3] RPC_IO_CFG_10_DRV_{n} (n=0..3), [2] RPC_IO_CFG_10_IBUFMD_2, [1] RPC_IO_CFG_10_IBUFMD_1, [0] RPC_IO_CFG_10_IBUFMD_0
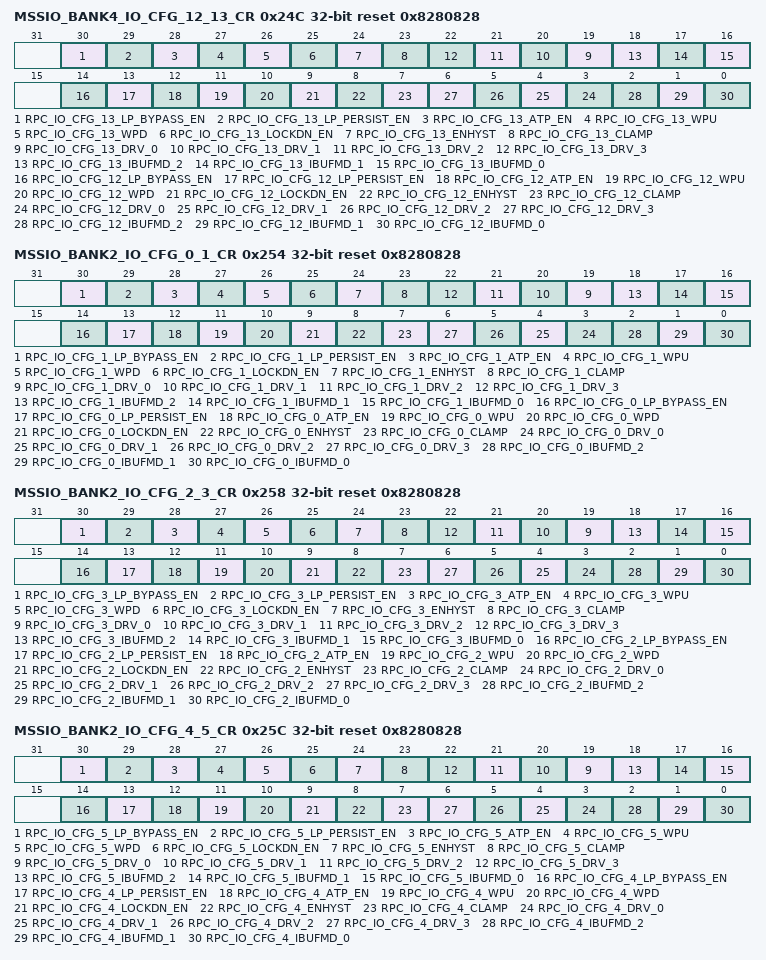
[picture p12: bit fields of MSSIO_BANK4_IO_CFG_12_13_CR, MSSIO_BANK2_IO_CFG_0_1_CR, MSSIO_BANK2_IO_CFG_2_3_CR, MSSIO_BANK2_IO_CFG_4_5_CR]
0x24C MSSIO_BANK4_IO_CFG_12_13_CR reset 0x8280828 — IO electrical configuration for MSSIO pad
  [30] RPC_IO_CFG_13_LP_BYPASS_EN, [29] RPC_IO_CFG_13_LP_PERSIST_EN, [28] RPC_IO_CFG_13_ATP_EN, [27] RPC_IO_CFG_13_WPU, [26] RPC_IO_CFG_13_WPD, [25] RPC_IO_CFG_13_LOCKDN_EN ro, [24] RPC_IO_CFG_13_ENHYST, [23] RPC_IO_CFG_13_CLAMP, [n+19] RPC_IO_CFG_13_DRV_{n} (n=0..3), [18] RPC_IO_CFG_13_IBUFMD_2, [17] RPC_IO_CFG_13_IBUFMD_1, [16] RPC_IO_CFG_13_IBUFMD_0, [14] RPC_IO_CFG_12_LP_BYPASS_EN, [13] RPC_IO_CFG_12_LP_PERSIST_EN, [12] RPC_IO_CFG_12_ATP_EN, [11] RPC_IO_CFG_12_WPU, [10] RPC_IO_CFG_12_WPD, [9] RPC_IO_CFG_12_LOCKDN_EN ro, [8] RPC_IO_CFG_12_ENHYST, [7] RPC_IO_CFG_12_CLAMP, [n+3] RPC_IO_CFG_12_DRV_{n} (n=0..3), [2] RPC_IO_CFG_12_IBUFMD_2, [1] RPC_IO_CFG_12_IBUFMD_1, [0] RPC_IO_CFG_12_IBUFMD_0
0x254 MSSIO_BANK2_IO_CFG_0_1_CR reset 0x8280828 — IO electrical configuration for MSSIO pad
  fields as MSSIO_BANK4_IO_CFG_0_1_CR
0x258 MSSIO_BANK2_IO_CFG_2_3_CR reset 0x8280828 — IO electrical configuration for MSSIO pad
  fields as MSSIO_BANK4_IO_CFG_2_3_CR
0x25C MSSIO_BANK2_IO_CFG_4_5_CR reset 0x8280828 — IO electrical configuration for MSSIO pad
  fields as MSSIO_BANK4_IO_CFG_4_5_CR
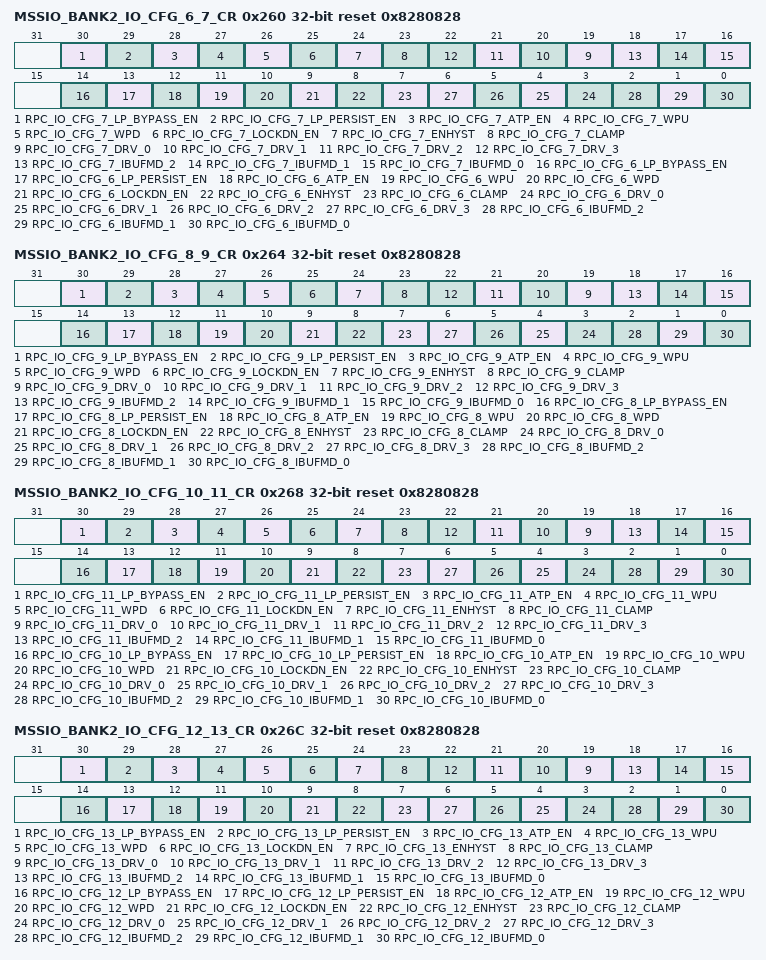
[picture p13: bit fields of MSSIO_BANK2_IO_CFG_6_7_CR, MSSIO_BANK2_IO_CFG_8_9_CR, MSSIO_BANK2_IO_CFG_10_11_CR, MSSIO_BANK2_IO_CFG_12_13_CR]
0x260 MSSIO_BANK2_IO_CFG_6_7_CR reset 0x8280828 — IO electrical configuration for MSSIO pad
  fields as MSSIO_BANK4_IO_CFG_6_7_CR
0x264 MSSIO_BANK2_IO_CFG_8_9_CR reset 0x8280828 — IO electrical configuration for MSSIO pad
  fields as MSSIO_BANK4_IO_CFG_8_9_CR
0x268 MSSIO_BANK2_IO_CFG_10_11_CR reset 0x8280828 — IO electrical configuration for MSSIO pad
  fields as MSSIO_BANK4_IO_CFG_10_11_CR
0x26C MSSIO_BANK2_IO_CFG_12_13_CR reset 0x8280828 — IO electrical configuration for MSSIO pad
  fields as MSSIO_BANK4_IO_CFG_12_13_CR
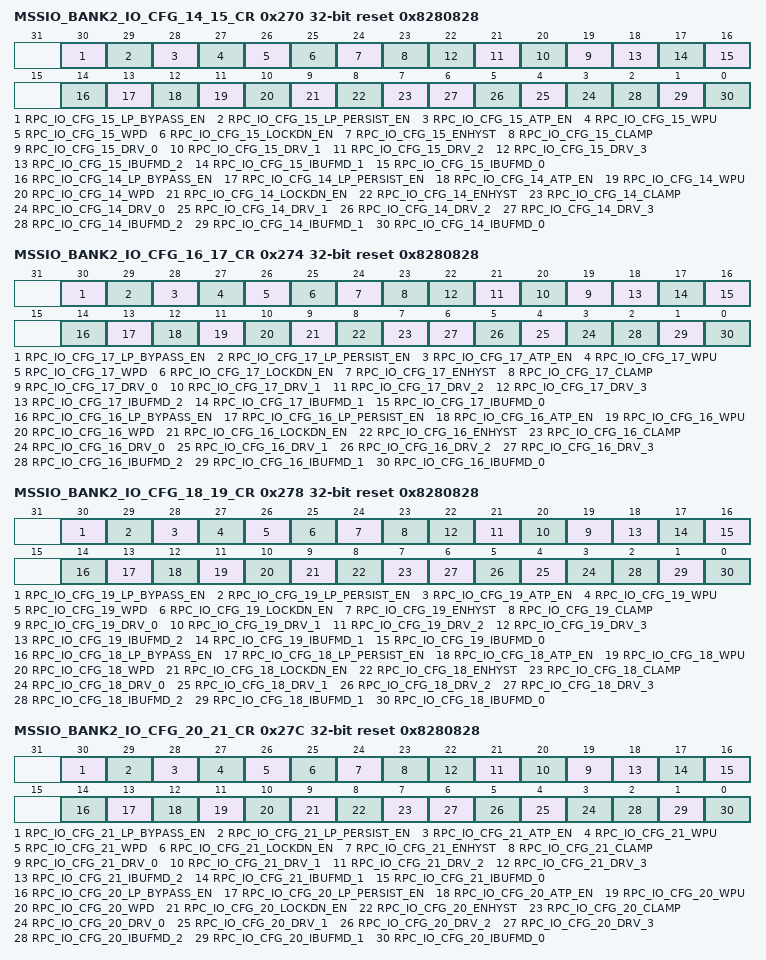
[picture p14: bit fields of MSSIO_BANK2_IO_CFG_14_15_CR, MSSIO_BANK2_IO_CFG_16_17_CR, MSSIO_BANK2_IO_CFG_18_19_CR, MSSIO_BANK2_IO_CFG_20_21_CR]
0x270 MSSIO_BANK2_IO_CFG_14_15_CR reset 0x8280828 — IO electrical configuration for MSSIO pad
  [30] RPC_IO_CFG_15_LP_BYPASS_EN, [29] RPC_IO_CFG_15_LP_PERSIST_EN, [28] RPC_IO_CFG_15_ATP_EN, [27] RPC_IO_CFG_15_WPU, [26] RPC_IO_CFG_15_WPD, [25] RPC_IO_CFG_15_LOCKDN_EN ro, [24] RPC_IO_CFG_15_ENHYST, [23] RPC_IO_CFG_15_CLAMP, [n+19] RPC_IO_CFG_15_DRV_{n} (n=0..3), [18] RPC_IO_CFG_15_IBUFMD_2, [17] RPC_IO_CFG_15_IBUFMD_1, [16] RPC_IO_CFG_15_IBUFMD_0, [14] RPC_IO_CFG_14_LP_BYPASS_EN, [13] RPC_IO_CFG_14_LP_PERSIST_EN, [12] RPC_IO_CFG_14_ATP_EN, [11] RPC_IO_CFG_14_WPU, [10] RPC_IO_CFG_14_WPD, [9] RPC_IO_CFG_14_LOCKDN_EN ro, [8] RPC_IO_CFG_14_ENHYST, [7] RPC_IO_CFG_14_CLAMP, [n+3] RPC_IO_CFG_14_DRV_{n} (n=0..3), [2] RPC_IO_CFG_14_IBUFMD_2, [1] RPC_IO_CFG_14_IBUFMD_1, [0] RPC_IO_CFG_14_IBUFMD_0
0x274 MSSIO_BANK2_IO_CFG_16_17_CR reset 0x8280828 — IO electrical configuration for MSSIO pad
  [30] RPC_IO_CFG_17_LP_BYPASS_EN, [29] RPC_IO_CFG_17_LP_PERSIST_EN, [28] RPC_IO_CFG_17_ATP_EN, [27] RPC_IO_CFG_17_WPU, [26] RPC_IO_CFG_17_WPD, [25] RPC_IO_CFG_17_LOCKDN_EN ro, [24] RPC_IO_CFG_17_ENHYST, [23] RPC_IO_CFG_17_CLAMP, [n+19] RPC_IO_CFG_17_DRV_{n} (n=0..3), [18] RPC_IO_CFG_17_IBUFMD_2, [17] RPC_IO_CFG_17_IBUFMD_1, [16] RPC_IO_CFG_17_IBUFMD_0, [14] RPC_IO_CFG_16_LP_BYPASS_EN, [13] RPC_IO_CFG_16_LP_PERSIST_EN, [12] RPC_IO_CFG_16_ATP_EN, [11] RPC_IO_CFG_16_WPU, [10] RPC_IO_CFG_16_WPD, [9] RPC_IO_CFG_16_LOCKDN_EN ro, [8] RPC_IO_CFG_16_ENHYST, [7] RPC_IO_CFG_16_CLAMP, [n+3] RPC_IO_CFG_16_DRV_{n} (n=0..3), [2] RPC_IO_CFG_16_IBUFMD_2, [1] RPC_IO_CFG_16_IBUFMD_1, [0] RPC_IO_CFG_16_IBUFMD_0
0x278 MSSIO_BANK2_IO_CFG_18_19_CR reset 0x8280828 — IO electrical configuration for MSSIO pad
  [30] RPC_IO_CFG_19_LP_BYPASS_EN, [29] RPC_IO_CFG_19_LP_PERSIST_EN, [28] RPC_IO_CFG_19_ATP_EN, [27] RPC_IO_CFG_19_WPU, [26] RPC_IO_CFG_19_WPD, [25] RPC_IO_CFG_19_LOCKDN_EN ro, [24] RPC_IO_CFG_19_ENHYST, [23] RPC_IO_CFG_19_CLAMP, [n+19] RPC_IO_CFG_19_DRV_{n} (n=0..3), [18] RPC_IO_CFG_19_IBUFMD_2, [17] RPC_IO_CFG_19_IBUFMD_1, [16] RPC_IO_CFG_19_IBUFMD_0, [14] RPC_IO_CFG_18_LP_BYPASS_EN, [13] RPC_IO_CFG_18_LP_PERSIST_EN, [12] RPC_IO_CFG_18_ATP_EN, [11] RPC_IO_CFG_18_WPU, [10] RPC_IO_CFG_18_WPD, [9] RPC_IO_CFG_18_LOCKDN_EN ro, [8] RPC_IO_CFG_18_ENHYST, [7] RPC_IO_CFG_18_CLAMP, [n+3] RPC_IO_CFG_18_DRV_{n} (n=0..3), [2] RPC_IO_CFG_18_IBUFMD_2, [1] RPC_IO_CFG_18_IBUFMD_1, [0] RPC_IO_CFG_18_IBUFMD_0
0x27C MSSIO_BANK2_IO_CFG_20_21_CR reset 0x8280828 — IO electrical configuration for MSSIO pad
  [30] RPC_IO_CFG_21_LP_BYPASS_EN, [29] RPC_IO_CFG_21_LP_PERSIST_EN, [28] RPC_IO_CFG_21_ATP_EN, [27] RPC_IO_CFG_21_WPU, [26] RPC_IO_CFG_21_WPD, [25] RPC_IO_CFG_21_LOCKDN_EN ro, [24] RPC_IO_CFG_21_ENHYST, [23] RPC_IO_CFG_21_CLAMP, [n+19] RPC_IO_CFG_21_DRV_{n} (n=0..3), [18] RPC_IO_CFG_21_IBUFMD_2, [17] RPC_IO_CFG_21_IBUFMD_1, [16] RPC_IO_CFG_21_IBUFMD_0, [14] RPC_IO_CFG_20_LP_BYPASS_EN, [13] RPC_IO_CFG_20_LP_PERSIST_EN, [12] RPC_IO_CFG_20_ATP_EN, [11] RPC_IO_CFG_20_WPU, [10] RPC_IO_CFG_20_WPD, [9] RPC_IO_CFG_20_LOCKDN_EN ro, [8] RPC_IO_CFG_20_ENHYST, [7] RPC_IO_CFG_20_CLAMP, [n+3] RPC_IO_CFG_20_DRV_{n} (n=0..3), [2] RPC_IO_CFG_20_IBUFMD_2, [1] RPC_IO_CFG_20_IBUFMD_1, [0] RPC_IO_CFG_20_IBUFMD_0
0x280 MSSIO_BANK2_IO_CFG_22_23_CR reset 0x8280828 — IO electrical configuration for MSSIO pad
  [30] RPC_IO_CFG_23_LP_BYPASS_EN, [29] RPC_IO_CFG_23_LP_PERSIST_EN, [28] RPC_IO_CFG_23_ATP_EN, [27] RPC_IO_CFG_23_WPU, [26] RPC_IO_CFG_23_WPD, [25] RPC_IO_CFG_23_LOCKDN_EN ro, [24] RPC_IO_CFG_23_ENHYST, [23] RPC_IO_CFG_23_CLAMP, [n+19] RPC_IO_CFG_23_DRV_{n} (n=0..3), [18] RPC_IO_CFG_23_IBUFMD_2, [17] RPC_IO_CFG_23_IBUFMD_1, [16] RPC_IO_CFG_23_IBUFMD_0, [14] RPC_IO_CFG_22_LP_BYPASS_EN, [13] RPC_IO_CFG_22_LP_PERSIST_EN, [12] RPC_IO_CFG_22_ATP_EN, [11] RPC_IO_CFG_22_WPU, [10] RPC_IO_CFG_22_WPD, [9] RPC_IO_CFG_22_LOCKDN_EN ro, [8] RPC_IO_CFG_22_ENHYST, [7] RPC_IO_CFG_22_CLAMP, [n+3] RPC_IO_CFG_22_DRV_{n} (n=0..3), [2] RPC_IO_CFG_22_IBUFMD_2, [1] RPC_IO_CFG_22_IBUFMD_1, [0] RPC_IO_CFG_22_IBUFMD_0
0x2A8 MSS_SPARE0_CR — Sets H2F [31:0] Spares out signals
  [31:0] DATA — See MSS MAS specification for full description
0x2AC MSS_SPARE1_CR — Sets H2F [37:32] Spares out signals
  [5:0] DATA — See MSS MAS specification for full description
0x2B0 MSS_SPARE0_SR ro — Read H2F [31:0] Spares out signals
  [31:0] DATA — See MSS MAS specification for full description
0x2B4 MSS_SPARE1_SR ro — Read H2F [37:32] Spares out signals
  [5:0] DATA — See MSS MAS specification for full description
0x2B8 MSS_SPARE2_SR ro — Read F2H [31:0] Spares in1 signals
  [31:0] DATA — See MSS MAS specification for full description
0x2BC MSS_SPARE3_SR ro — Read F2H [37:32] Spares in1 signals
  [5:0] DATA — See MSS MAS specification for full description
0x2C0 MSS_SPARE4_SR ro — Read F2H [31:0] Spares in2 signals
  [31:0] DATA — See MSS MAS specification for full description
0x2C4 MSS_SPARE5_SR ro — Read F2H [37:32] Spares in2 signals
  [5:0] DATA — See MSS MAS specification for full description
0x2D0 SPARE_REGISTER_RW — Register for ECO usage
  [7:0] DATA — No function, provided for future ECO use
0x2D4 SPARE_REGISTER_W1P — Register for ECO usage
  [7:0] DATA — No function, provided for future ECO use
0x2D8 SPARE_REGISTER_RO ro — Register for ECO usage
  [15:0] DATA — Provides readback of { W1P, RW } registers. No function, provided for future ECO use.
0x2DC SPARE_PERIM_RW — Spare signal back to PFC
  [9] MMUART0_RXD — When set MMUART0 RXD is received on perimeter 5 from PFC. When enabled in PFC it the SPI SDI input is drives this connection. When enabled the PFC QSPI interrupt is disabled. (This function intended for manufacturing use only)
  [8] MMUART0_TXD — When set MMUART0 TXD is sent on Perimeter 2 to PFC, when enabled in PFC it will be output on the SPI SDO pin. (This function intended for manufacturing use only)
  [6:4] DATA — Controls perim_spare_out bits 5 7 & 9 when the ENABLE bits set
  [2:0] ENABLE — Allows the MSS to control the perim_spare_out bits 5 7 & 9. No function, provided for future ECO use.
0x2E0 SPARE_FIC ro — Unused FIC resets
  [3:0] RESET — Connected to spare FIC 0-3 Reset inputs to provide simple RO bits. No defined use
